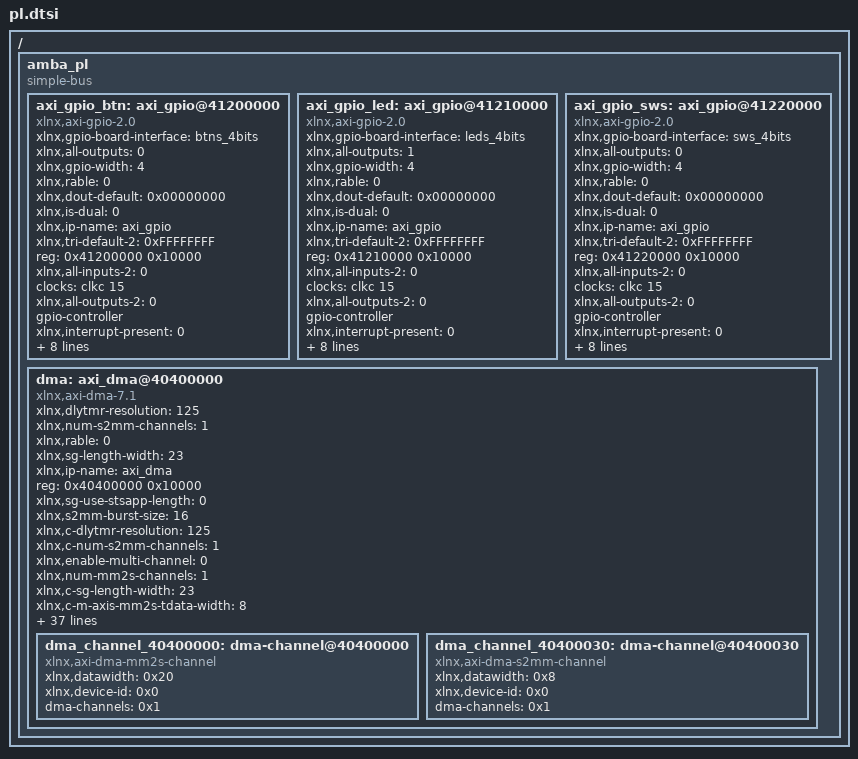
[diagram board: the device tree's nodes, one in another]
/ {
	amba_pl: amba_pl {
		ranges;
		compatible = "simple-bus";
		#address-cells = <1>;
		#size-cells = <1>;
		axi_gpio_btn: axi_gpio@41200000 {
			xlnx,gpio-board-interface = "btns_4bits";
			compatible = "xlnx,axi-gpio-2.0" , "xlnx,xps-gpio-1.00.a";
			xlnx,all-outputs = <0>;
			#gpio-cells = <2>;
			xlnx,gpio-width = <4>;
			xlnx,rable = <0>;
			xlnx,dout-default = <0x00000000>;
			xlnx,is-dual = <0>;
			xlnx,ip-name = "axi_gpio";
			xlnx,tri-default-2 = <0xFFFFFFFF>;
			reg = <0x41200000 0x10000>;
			xlnx,all-inputs-2 = <0>;
			clocks = <&clkc 15>;
			xlnx,all-outputs-2 = <0>;
			gpio-controller;
			xlnx,interrupt-present = <0>;
			xlnx,gpio2-board-interface = "Custom";
			xlnx,edk-iptype = "PERIPHERAL";
			xlnx,dout-default-2 = <0x00000000>;
			xlnx,gpio2-width = <32>;
			status = "okay";
			clock-names = "s_axi_aclk";
			xlnx,use-board-flow;
			xlnx,tri-default = <0xFFFFFFFF>;
			xlnx,name = "axi_gpio_btn";
			xlnx,all-inputs = <1>;
		};
		axi_gpio_led: axi_gpio@41210000 {
			xlnx,gpio-board-interface = "leds_4bits";
			compatible = "xlnx,axi-gpio-2.0" , "xlnx,xps-gpio-1.00.a";
			xlnx,all-outputs = <1>;
			#gpio-cells = <2>;
			xlnx,gpio-width = <4>;
			xlnx,rable = <0>;
			xlnx,dout-default = <0x00000000>;
			xlnx,is-dual = <0>;
			xlnx,ip-name = "axi_gpio";
			xlnx,tri-default-2 = <0xFFFFFFFF>;
			reg = <0x41210000 0x10000>;
			xlnx,all-inputs-2 = <0>;
			clocks = <&clkc 15>;
			xlnx,all-outputs-2 = <0>;
			gpio-controller;
			xlnx,interrupt-present = <0>;
			xlnx,gpio2-board-interface = "Custom";
			xlnx,edk-iptype = "PERIPHERAL";
			xlnx,dout-default-2 = <0x00000000>;
			xlnx,gpio2-width = <32>;
			status = "okay";
			clock-names = "s_axi_aclk";
			xlnx,use-board-flow;
			xlnx,tri-default = <0xFFFFFFFF>;
			xlnx,name = "axi_gpio_led";
			xlnx,all-inputs = <0>;
		};
		axi_gpio_sws: axi_gpio@41220000 {
			xlnx,gpio-board-interface = "sws_4bits";
			compatible = "xlnx,axi-gpio-2.0" , "xlnx,xps-gpio-1.00.a";
			xlnx,all-outputs = <0>;
			#gpio-cells = <2>;
			xlnx,gpio-width = <4>;
			xlnx,rable = <0>;
			xlnx,dout-default = <0x00000000>;
			xlnx,is-dual = <0>;
			xlnx,ip-name = "axi_gpio";
			xlnx,tri-default-2 = <0xFFFFFFFF>;
			reg = <0x41220000 0x10000>;
			xlnx,all-inputs-2 = <0>;
			clocks = <&clkc 15>;
			xlnx,all-outputs-2 = <0>;
			gpio-controller;
			xlnx,interrupt-present = <0>;
			xlnx,gpio2-board-interface = "Custom";
			xlnx,edk-iptype = "PERIPHERAL";
			xlnx,dout-default-2 = <0x00000000>;
			xlnx,gpio2-width = <32>;
			status = "okay";
			clock-names = "s_axi_aclk";
			xlnx,use-board-flow;
			xlnx,tri-default = <0xFFFFFFFF>;
			xlnx,name = "axi_gpio_sws";
			xlnx,all-inputs = <1>;
		};
		dma: axi_dma@40400000 {
			xlnx,dlytmr-resolution = <125>;
			xlnx,num-s2mm-channels = <1>;
			xlnx,rable = <0>;
			xlnx,sg-length-width = <23>;
			xlnx,ip-name = "axi_dma";
			reg = <0x40400000 0x10000>;
			xlnx,sg-use-stsapp-length = <0>;
			xlnx,s2mm-burst-size = <16>;
			xlnx,c-dlytmr-resolution = <125>;
			xlnx,c-num-s2mm-channels = <1>;
			xlnx,enable-multi-channel = <0>;
			xlnx,num-mm2s-channels = <1>;
			xlnx,c-sg-length-width = <23>;
			compatible = "xlnx,axi-dma-7.1" , "xlnx,axi-dma-1.00.a";
			xlnx,c-m-axis-mm2s-tdata-width = <8>;
			xlnx,c-sg-use-stsapp-length = <0>;
			xlnx,c-s2mm-burst-size = <16>;
			xlnx,mm2s-burst-size = <16>;
			xlnx,c-enable-multi-channel = <0>;
			xlnx,c-num-mm2s-channels = <1>;
			xlnx,include-s2mm-dre = <0>;
			xlnx,c-mm2s-burst-size = <16>;
			status = "okay";
			xlnx,c-include-s2mm-dre = <0>;
			xlnx,include-mm2s-dre = <0>;
			xlnx,name = "dma";
			xlnx,c-include-sg = <0>;
			xlnx,c-m-axi-s2mm-data-width = <32>;
			xlnx,include-s2mm-sf = <1>;
			xlnx,c-include-mm2s-dre = <0>;
			xlnx,include-s2mm = <1>;
			clocks = <&clkc 15>, <&clkc 15>, <&clkc 15>;
			xlnx,addrwidth = <0x20>;
			xlnx,c-m-axi-mm2s-data-width = <32>;
			xlnx,edk-iptype = "PERIPHERAL";
			xlnx,c-include-s2mm-sf = <1>;
			xlnx,include-mm2s-sf = <1>;
			clock-names = "m_axi_mm2s_aclk" , "m_axi_s2mm_aclk" , "s_axi_lite_aclk";
			xlnx,c-include-s2mm = <1>;
			xlnx,c-addr-width = <32>;
			xlnx,c-single-interface = <0>;
			xlnx,include-mm2s = <1>;
			xlnx,c-s-axis-s2mm-tdata-width = <8>;
			xlnx,s2mm-data-width = <0x20>;
			xlnx,c-include-mm2s-sf = <1>;
			xlnx,prmry-is-aclk-async = <0>;
			xlnx,c-include-mm2s = <1>;
			xlnx,increase-throughput = <0>;
			xlnx,micro-dma = <0>;
			xlnx,mm2s-data-width = <0x20>;
			xlnx,c-prmry-is-aclk-async = <0>;
			xlnx,c-sg-include-stscntrl-strm = <0>;
			xlnx,c-increase-throughput = <0>;
			xlnx,c-micro-dma = <0>;
			dma_channel_40400000: dma-channel@40400000 {
				xlnx,datawidth = <0x20>;
				xlnx,device-id = <0x0>;
				compatible = "xlnx,axi-dma-mm2s-channel";
				dma-channels = <0x1>;
			};
			dma_channel_40400030: dma-channel@40400030 {
				xlnx,datawidth = <0x8>;
				xlnx,device-id = <0x0>;
				compatible = "xlnx,axi-dma-s2mm-channel";
				dma-channels = <0x1>;
			};
		};
	};
};
